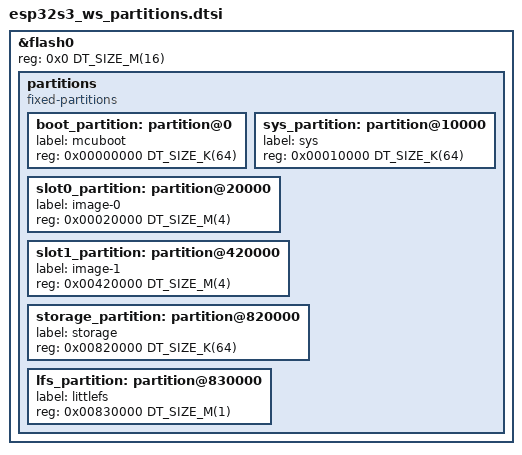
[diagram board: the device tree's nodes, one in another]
/*
 * Flash layout of the weatherstation on a 16 MB ESP32-S3 module.
 * Shared by the application and MCUboot (sysbuild/mcuboot.overlay).
 */
&flash0 {
	reg = <0x0 DT_SIZE_M(16)>;
};

/delete-node/ &boot_partition;
/delete-node/ &sys_partition;
/delete-node/ &slot0_partition;
/delete-node/ &slot1_partition;
/delete-node/ &slot0_appcpu_partition;
/delete-node/ &slot1_appcpu_partition;
/delete-node/ &slot0_lpcore_partition;
/delete-node/ &slot1_lpcore_partition;
/delete-node/ &storage_partition;
/delete-node/ &scratch_partition;
/delete-node/ &coredump_partition;

&flash0 {
	partitions {
		compatible = "fixed-partitions";
		#address-cells = <1>;
		#size-cells = <1>;

		boot_partition: partition@0 {
			label = "mcuboot";
			reg = <0x00000000 DT_SIZE_K(64)>;
		};
		sys_partition: partition@10000 {
			label = "sys";
			reg = <0x00010000 DT_SIZE_K(64)>;
		};
		slot0_partition: partition@20000 {
			label = "image-0";
			reg = <0x00020000 DT_SIZE_M(4)>;
		};
		slot1_partition: partition@420000 {
			label = "image-1";
			reg = <0x00420000 DT_SIZE_M(4)>;
		};
		storage_partition: partition@820000 {
			label = "storage";
			reg = <0x00820000 DT_SIZE_K(64)>;
		};
		lfs_partition: partition@830000 {
			label = "littlefs";
			reg = <0x00830000 DT_SIZE_M(1)>;
		};
	};
};
